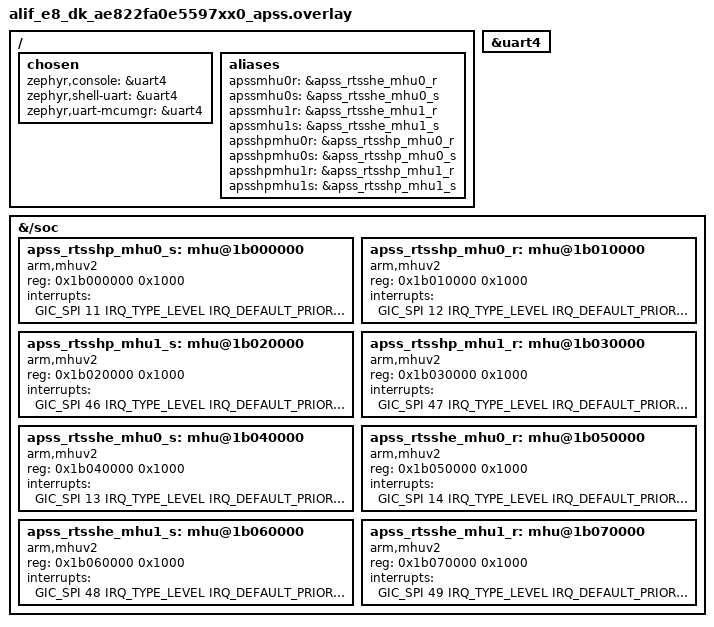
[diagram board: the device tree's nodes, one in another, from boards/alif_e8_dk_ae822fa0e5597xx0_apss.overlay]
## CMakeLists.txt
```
# Copyright (C) Alif Semiconductor - All Rights Reserved.
# Use, distribution and modification of this code is permitted under the
# terms stated in the Alif Semiconductor Software License Agreement
#
# You should have received a copy of the Alif Semiconductor Software
# License Agreement with this file. If not, please write to:
# contact@alifsemi.com, or visit: https://alifsemi.com/license

cmake_minimum_required(VERSION 3.20.0)
find_package(Zephyr REQUIRED HINTS $ENV{ZEPHYR_BASE})
project(ipm_arm_mhu_doorbell)

target_include_directories(app PRIVATE include)

target_sources_ifdef(CONFIG_HE_HP_S  app PRIVATE src/m55he_to_m55hp_initiator.c)
target_sources_ifdef(CONFIG_HP_HE_R  app PRIVATE src/m55hp_to_m55he_responder.c)
target_sources_ifdef(CONFIG_HE_A32_S app PRIVATE src/m55_to_a32_initiator.c)
target_sources_ifdef(CONFIG_A32_HE_R app PRIVATE src/a32_to_m55_responder.c)
```

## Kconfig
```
# Copyright (C) Alif Semiconductor - All Rights Reserved.
# Use, distribution and modification of this code is permitted under the
# terms stated in the Alif Semiconductor Software License Agreement

mainmenu "MHU Doorbell Sample Configuration"

choice
	prompt "MHU doorbell test case"
	default HE_HP_S
	help
	  Select which inter-processor communication test case to build.
	  Exactly one test case is built per image.

config HE_HP_S
	bool "RTSS-HE (M55) to RTSS-HP (M55) initiator/sender"
	help
	  Build the RTSS-HE (M55) to RTSS-HP (M55) shared memory &
	  doorbell initiator/sender.

config HP_HE_R
	bool "RTSS-HP (M55) to RTSS-HE (M55) responder"
	help
	  Build the RTSS-HP (M55) to RTSS-HE (M55) shared memory &
	  doorbell responder.

config HE_A32_S
	bool "RTSS-HE (M55) to APSS (A32) initiator/sender"
	help
	  Build the RTSS-HE (M55) to APSS (A32) shared memory &
	  doorbell initiator/sender.

config A32_HE_R
	bool "APSS (A32) to RTSS-HE (M55) responder"
	help
	  Build the APSS (A32, Zephyr) responder for messages initiated by
	  the RTSS-HE (M55) shared memory & doorbell initiator (counterpart
	  to CONFIG_HE_A32_S).

endchoice

config USE_MHU1
	bool "Use MHU1 instead of MHU0 for inter-core communication"
	default n
	help
	  Select MHU1 channel for communication between M55 cores.
	  Default is MHU0.

source "Kconfig.zephyr"

# Automatically enable power management when one of the pm-system-off-*
# snippets is applied. Those snippets enable the aipm-off DTS node, so the
# default build (without the snippet) is unaffected.
config PM
	default y if $(dt_nodelabel_enabled,aipm_off)

config COUNTER
	default y if $(dt_nodelabel_enabled,aipm_off)
```

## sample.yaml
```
---
sample:
  name: MHU Doorbell & Shared SRAM Sample
tests:
  sample.drivers.ipm.arm_mhu_doorbell:
    tags: doorbell
    platform_allow:
      - alif_e8_dk/ae822fa0e5597xx0/rtss_he
      - alif_e8_dk/ae822fa0e5597xx0/rtss_hp
```

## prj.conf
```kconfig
# The test case (CONFIG_HE_HP_S / CONFIG_HP_HE_R / CONFIG_HE_A32_S /
# CONFIG_A32_HE_R) and options such as CONFIG_USE_MHU1 are selected on the
# command line -- see README.rst. Low-power operation is enabled via the
# pm-system-off-* snippets (PM and COUNTER are turned on automatically in
# Kconfig when the snippet's aipm-off node is present), so no additional
# Kconfig settings are needed here.
```

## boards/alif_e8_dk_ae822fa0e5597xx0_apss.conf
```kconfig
# SPDX-FileCopyrightText: Copyright Alif Semiconductor
# SPDX-License-Identifier: Apache-2.0

# The APSS (A32) board defconfig does not enable MHU support (the A32 normally
# has no MHU nodes). This sample adds them via the board overlay, so pull in
# the SoC MHUv2 support here -- it selects IPM and ARM_MHUV2 -- for the A32
# responder build (CONFIG_A32_HE_R).
CONFIG_SOC_SUPPORT_ARM_MHUV2=y
```

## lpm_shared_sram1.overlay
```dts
/* Copyright (C) Alif Semiconductor - All Rights Reserved.
 * Use, distribution and modification of this code is permitted under the
 * terms stated in the Alif Semiconductor Software License Agreement
 *
 * You should have received a copy of the Alif Semiconductor Software
 * License Agreement with this file. If not, please write to:
 * contact@alifsemi.com, or visit: https://alifsemi.com/license
 *
 * Keep the cross-core shared heap (SRAM1) powered AND keep the VBAT_AON power
 * domain (which hosts the LPRTC idle-timer) alive when the pm-system-off-*
 * snippets are applied.
 *
 * The HE<->HP doorbell protocol exchanges data through a struct sys_heap that
 * lives in SRAM1 (0x027DC000 / 0x027DC800), and HE uses the LPRTC
 * (rtc0 = lprtc@42000000, chosen zephyr,cortex-m-idle-timer) to wake itself
 * from PM_STATE_SUSPEND_TO_IDLE for each timed k_sleep().
 *
 * The Secure Enclave only lowers a power domain / drops a memory block when
 * ALL participating cores vote for it. The pm-system-off-* snippets set the
 * run profile to:
 *   - retain ONLY MRAM (memory-blocks = <ALIF_MRAM_MASK>)
 *   - keep ONLY SSE700_AON + SYST powered (power-domains = 0x44), dropping
 *     VBAT_AON.
 * The LPRTC at 0x42000000 lives in the VBAT_AON domain. When only one core is
 * PM-managed the other (fully-on) core keeps both SRAM1 and VBAT_AON alive, so
 * the protocol works. As soon as BOTH cores run a snippet, neither votes to
 * keep VBAT_AON powered -> the SE gates it -> the LPRTC stops counting -> HE's
 * very first k_sleep() never wakes and the system HANGS. (The same applies to
 * SRAM1 retention for the shared heap.)
 *
 * Override the run profile to (a) retain SRAM1 and (b) keep VBAT_AON powered.
 * This must be applied AFTER the snippet overlay. Only a command-line
 * EXTRA_DTC_OVERLAY_FILE is applied after the snippet (the app's
 * boards/<board>.overlay and any overlay appended from CMakeLists before
 * find_package are applied BEFORE the snippet and lose to it). So pass this
 * file explicitly on the west command line, e.g.:
 *   HE: -DEXTRA_DTC_OVERLAY_FILE="lpuart.overlay;lpm_shared_sram1.overlay"
 *   HP: -DEXTRA_DTC_OVERLAY_FILE=lpm_shared_sram1.overlay
 */

&aipm_run_default {
	/* Retain the shared heap (SRAM1) in addition to MRAM. */
	memory-blocks = <(ALIF_MRAM_MASK | ALIF_SRAM1_MASK)>;
	/* Keep VBAT_AON powered so the LPRTC idle-timer keeps ticking and can
	 * wake HE from SUSPEND_TO_IDLE; SSE700_AON + SYST as per the snippet.
	 */
	aipm-power-domains = <(ALIF_PD_VBAT_AON_MASK |
			       ALIF_PD_SSE700_AON_MASK |
			       ALIF_PD_SYST_MASK)>;
};

/* HE idles into PM_STATE_SUSPEND_TO_IDLE during the protocol; the
 * pm-system-off-he snippet already enables this node. The pm-system-off-hp
 * snippet does not, so enable it here. Suspend-to-idle uses the IWIC, which
 * wakes on the MHU RX IRQ (and, on HE, the rtc0 idle-timer), so no extra wake
 * configuration is needed. (HP itself uses SOFT_OFF, but leaving this enabled
 * is harmless as HP locks SUSPEND_TO_IDLE out at runtime.)
 */
&suspend_idle {
	status = "okay";
};

/* Keep SRAM1 powered across SOFT_OFF so the cross-core shared heap memory stays
 * valid while a core is off. The sample re-initialises the heap on each
 * reset-based wake, so this only keeps SRAM1 powered and does not rely on any
 * state surviving a SOFT_OFF cycle. The pm-system-off-*
 * snippets retain only MRAM (+SERAM on HP) in the off profile, which would drop
 * SRAM1 when a core powers off. Setting only memory-blocks here leaves the
 * snippet's wakeup-events / ewic-cfg untouched. (HP's MHU wake comes from the
 * M55 EWIC auto-monitoring enabled NVIC IRQs 0-63 -- MHU0=41, MHU1=43 -- not
 * from the off-profile AON ewic-cfg.)
 */
&off_profile_soft_off {
	memory-blocks = <(ALIF_MRAM_MASK | ALIF_SERAM_MASK | ALIF_SRAM1_MASK)>;
};
```

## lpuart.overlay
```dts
/* Copyright (C) Alif Semiconductor - All Rights Reserved.
 * Use, distribution and modification of this code is permitted under the
 * terms stated in the Alif Semiconductor Software License Agreement
 *
 * You should have received a copy of the Alif Semiconductor Software
 * License Agreement with this file. If not, please write to:
 * contact@alifsemi.com, or visit: https://alifsemi.com/license
 */

&uart2 {
	status = "disabled";
};

&lpuart {
	current-speed = <115200>;
	dlf = <13>;
	/*/delete-property/ dlf;*/
	status = "okay";
	/delete-property/ pinctrl-1; // = <&pinctrl_lpuart_sleep>;
	pinctrl-names = "default";
};

&pinctrl {
	pinctrl_lpuart: pinctrl_lpuart {
		group0 {
			pinmux = < PIN_P9_1__LPUART_RX_B >,
				 < PIN_P9_2__LPUART_TX_B >;
		};
	};
};
/ {
	chosen {
		zephyr,console = &lpuart;
		zephyr,shell-uart = &lpuart;
		zephyr,uart-mcumgr = &lpuart;
	};
};
/*
 * Enable PM_STATE_SOFT_OFF wake for the HE core via the always-on LPTIMER0.
 *
 * The pm-system-off-he snippet only configures the S2RAM off-profiles
 * (off_profile_standby / off_profile_stop -> LPRTC wake) and leaves
 * off_profile_soft_off at its default (wakeup-events = 0, ewic-cfg = 0), so
 * SOFT_OFF on HE has no wake source and never resumes. Mirror the HP snippet
 * and wake SOFT_OFF from LPTIMER0 (VBAT timer, EWIC VBAT_TIMER).
 *
 * Only a command-line EXTRA_DTC_OVERLAY_FILE is applied AFTER the snippet, so
 * this override must live in an overlay passed on the west command line (this
 * file). Enabling timer0 also lets main.c arm LPTIMER0 before entering
 * SOFT_OFF, since the LPRTC idle-timer is powered down in that profile.
 */
&timer0 {
	status = "okay";
};

/*
 * The pm-system-off-he snippet sets aipm_off vtor-address = 0x0, i.e. it tells
 * the Secure Enclave to restore VTOR to TCM (0x0) when the core wakes from the
 * off profile. That is correct for a TCM-boot image (S2RAM resume in place),
 * but this build boots from MRAM (VTOR = 0x80000000). On wake from SOFT_OFF the
 * SE would jump to the empty TCM at 0x0 and the core would never restart, so no
 * reset is observed. Point the wake vector back at the MRAM image start so
 * SOFT_OFF wakeup performs a clean reset/reboot (as it does on the HP core,
 * whose snippet does not override vtor-address).
 */
&aipm_off {
	vtor-address = <0x80000000>;
};

&off_profile_soft_off {
	status = "okay";
	/* Keep SRAM1 powered across SOFT_OFF so the cross-core shared heap
	 * memory stays valid while HE is off. The sample re-initialises the
	 * heap on each reset-based wake and does not rely on any state
	 * surviving a SOFT_OFF cycle.
	 */
	memory-blocks = <(ALIF_MRAM_MASK | ALIF_SERAM_MASK | ALIF_SRAM1_MASK)>;
	wakeup-events = <ALIF_WE_LPTIMER0>;
	ewic-cfg = <ALIF_EWIC_VBAT_TIMER>;
};

/*
 * The m55he_to_m55hp_initiator.c flow re-enters SOFT_OFF between doorbell
 * exchanges and arms LPTIMER0 for a 2 s wake. Lower the SOFT_OFF (subsys_off)
 * min-residency below 2 s (snippet default is 25 s) so the PM policy actually
 * selects SOFT_OFF for that 2 s k_sleep().
 */
&subsys_off {
	min-residency-us = <500000>;
};
```

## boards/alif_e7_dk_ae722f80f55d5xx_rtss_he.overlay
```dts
/* Copyright (C) Alif Semiconductor - All Rights Reserved.
 * Use, distribution and modification of this code is permitted under the
 * terms stated in the Alif Semiconductor Software License Agreement
 *
 * You should have received a copy of the Alif Semiconductor Software
 * License Agreement with this file. If not, please write to:
 * contact@alifsemi.com, or visit: https://alifsemi.com/license
 *
 */
#include "alif_ensemble_dk.overlay"
```

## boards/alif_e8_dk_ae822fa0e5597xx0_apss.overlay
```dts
/*
 * SPDX-FileCopyrightText: Copyright Alif Semiconductor
 * SPDX-License-Identifier: Apache-2.0
 *
 * APSS (A32) board overlay for the MHU doorbell sample.
 *
 * The A32 is the peer of the RTSS-HE core: it receives the doorbell the
 * RTSS-HE initiator sends and replies back. Unlike the M55 cores (NVIC), the
 * A32 reaches the MHU register frames through the GIC.
 *
 * Register bases and GIC SPI interrupts are the A32-side MHU frames for the
 * RTSS-HE and RTSS-HP channels on the Alif devkit-e8:
 *   hp_mhu0_tx @ 0x1b000000  GIC_SPI 11
 *   hp_mhu0_rx @ 0x1b010000  GIC_SPI 12
 *   hp_mhu1_tx @ 0x1b020000  GIC_SPI 46
 *   hp_mhu1_rx @ 0x1b030000  GIC_SPI 47
 *   he_mhu0_tx @ 0x1b040000  GIC_SPI 13
 *   he_mhu0_rx @ 0x1b050000  GIC_SPI 14
 *   he_mhu1_tx @ 0x1b060000  GIC_SPI 48
 *   he_mhu1_rx @ 0x1b070000  GIC_SPI 49
 *
 * The shared SRAM1 heap (0x027DDxxx) is not in the A32's default MMU map; the
 * responder maps it at runtime, non-cacheable, via k_mem_map_phys_bare().
 */

#include <zephyr/dt-bindings/interrupt-controller/arm-gic.h>

/ {
	chosen {
		zephyr,console = &uart4;
		zephyr,shell-uart = &uart4;
		zephyr,uart-mcumgr = &uart4;
	};

	aliases {
		apssmhu0r = &apss_rtsshe_mhu0_r;
		apssmhu0s = &apss_rtsshe_mhu0_s;
		apssmhu1r = &apss_rtsshe_mhu1_r;
		apssmhu1s = &apss_rtsshe_mhu1_s;
		apsshpmhu0r = &apss_rtsshp_mhu0_r;
		apsshpmhu0s = &apss_rtsshp_mhu0_s;
		apsshpmhu1r = &apss_rtsshp_mhu1_r;
		apsshpmhu1s = &apss_rtsshp_mhu1_s;
	};
};

&uart4 {
	status = "okay";
};

&{/soc} {
	/* MHU0 sender: A32 sends to RTSS-HP */
	apss_rtsshp_mhu0_s: mhu@1b000000 {
		compatible = "arm,mhuv2";
		reg = <0x1b000000 0x1000>;
		interrupts = <GIC_SPI 11 IRQ_TYPE_LEVEL IRQ_DEFAULT_PRIORITY>;
		interrupt-names = "tx";
		status = "okay";
	};

	/* MHU0 receiver: A32 receives from RTSS-HP */
	apss_rtsshp_mhu0_r: mhu@1b010000 {
		compatible = "arm,mhuv2";
		reg = <0x1b010000 0x1000>;
		interrupts = <GIC_SPI 12 IRQ_TYPE_LEVEL IRQ_DEFAULT_PRIORITY>;
		interrupt-names = "rx";
		status = "okay";
	};

	/* MHU1 sender: A32 sends to RTSS-HP */
	apss_rtsshp_mhu1_s: mhu@1b020000 {
		compatible = "arm,mhuv2";
		reg = <0x1b020000 0x1000>;
		interrupts = <GIC_SPI 46 IRQ_TYPE_LEVEL IRQ_DEFAULT_PRIORITY>;
		interrupt-names = "tx";
		status = "okay";
	};

	/* MHU1 receiver: A32 receives from RTSS-HP */
	apss_rtsshp_mhu1_r: mhu@1b030000 {
		compatible = "arm,mhuv2";
		reg = <0x1b030000 0x1000>;
		interrupts = <GIC_SPI 47 IRQ_TYPE_LEVEL IRQ_DEFAULT_PRIORITY>;
		interrupt-names = "rx";
		status = "okay";
	};

	/* MHU0 sender: A32 sends to RTSS-HE */
	apss_rtsshe_mhu0_s: mhu@1b040000 {
		compatible = "arm,mhuv2";
		reg = <0x1b040000 0x1000>;
		interrupts = <GIC_SPI 13 IRQ_TYPE_LEVEL IRQ_DEFAULT_PRIORITY>;
		interrupt-names = "tx";
		status = "okay";
	};

	/* MHU0 receiver: A32 receives from RTSS-HE */
	apss_rtsshe_mhu0_r: mhu@1b050000 {
		compatible = "arm,mhuv2";
		reg = <0x1b050000 0x1000>;
		interrupts = <GIC_SPI 14 IRQ_TYPE_LEVEL IRQ_DEFAULT_PRIORITY>;
		interrupt-names = "rx";
		status = "okay";
	};

	/* MHU1 sender: A32 sends to RTSS-HE */
	apss_rtsshe_mhu1_s: mhu@1b060000 {
		compatible = "arm,mhuv2";
		reg = <0x1b060000 0x1000>;
		interrupts = <GIC_SPI 48 IRQ_TYPE_LEVEL IRQ_DEFAULT_PRIORITY>;
		interrupt-names = "tx";
		status = "okay";
	};

	/* MHU1 receiver: A32 receives from RTSS-HE */
	apss_rtsshe_mhu1_r: mhu@1b070000 {
		compatible = "arm,mhuv2";
		reg = <0x1b070000 0x1000>;
		interrupts = <GIC_SPI 49 IRQ_TYPE_LEVEL IRQ_DEFAULT_PRIORITY>;
		interrupt-names = "rx";
		status = "okay";
	};
};
```

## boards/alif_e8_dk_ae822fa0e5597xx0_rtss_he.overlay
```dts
/* Copyright (C) Alif Semiconductor - All Rights Reserved.
 * Use, distribution and modification of this code is permitted under the
 * terms stated in the Alif Semiconductor Software License Agreement
 *
 * You should have received a copy of the Alif Semiconductor Software
 * License Agreement with this file. If not, please write to:
 * contact@alifsemi.com, or visit: https://alifsemi.com/license
 *
 */
#include "alif_ensemble_dk.overlay"
/*
 * /{
 *	chosen {
 *		zephyr,console = &uart4;
 *		zephyr,shell-uart = &uart4;
 *		zephyr,uart-mcumgr = &uart4;
 *	};
 * };
 *
 * &uart4 {
 *	status = "okay";
 * };
 */
```

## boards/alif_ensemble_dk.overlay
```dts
/* Copyright (C) Alif Semiconductor - All Rights Reserved.
 * Use, distribution and modification of this code is permitted under the
 * terms stated in the Alif Semiconductor Software License Agreement
 *
 * You should have received a copy of the Alif Semiconductor Software
 * License Agreement with this file. If not, please write to:
 * contact@alifsemi.com, or visit: https://alifsemi.com/license
 *
 */

/{
	aliases {
		apssmhu0r = &apss_rtsshe_mhu0_r;
		apssmhu0s = &rtsshe_apss_mhu0_s;
		apssmhu1r = &apss_rtsshe_mhu1_r;
		apssmhu1s = &rtsshe_apss_mhu1_s;
		rtssmhu0r = &rtsshp_rtsshe_mhu0_r;
		rtssmhu0s = &rtsshe_rtsshp_mhu0_s;
		rtssmhu1r = &rtsshp_rtsshe_mhu1_r;
		rtssmhu1s = &rtsshe_rtsshp_mhu1_s;
	};
};
```

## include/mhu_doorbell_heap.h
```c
/* Copyright (C) Alif Semiconductor - All Rights Reserved.
 * Use, distribution and modification of this code is permitted under the
 * terms stated in the Alif Semiconductor Software License Agreement
 *
 * You should have received a copy of the Alif Semiconductor Software
 * License Agreement with this file. If not, please write to:
 * contact@alifsemi.com, or visit: https://alifsemi.com/license
 *
 * Shared SRAM1 cross-core heap layout for the MHU doorbell sample.
 *
 * Each shared heap is a struct sys_heap control block immediately followed by
 * the memory it manages, both placed in shared SRAM1 so the two participating
 * cores operate on the same heap instance. The control block plus managed
 * memory occupy one SHARED_HEAP_SPAN region; the managed area itself is
 * SHARED_HEAP_SIZE bytes. There is one heap per MHU channel.
 *
 * The addresses are a fixed contract shared by every participant (M55-HE,
 * M55-HP and the A32/APSS side), so they live in one header rather than being
 * duplicated per test case. The A32 (HE<->A32) heaps are page-aligned and each
 * whole span fits in one 4 KB page so the A32 side can reach every block
 * through a single mapping.
 *
 * The region sits 0x24000 below the end of SRAM1, whose location differs per
 * SoC series:
 *   E8: SRAM1 0x02400000 (4 MB)   -> SHARED_HEAP_BASE 0x027DC000
 *   E7: SRAM1 0x08000000 (2.5 MB) -> SHARED_HEAP_BASE 0x0825C000
 * The base is selected by SoC series rather than taken from the devicetree
 * because the APSS devicetree has no sram1 node.
 *
 *   SRAM1 layout relative to SHARED_HEAP_BASE (ctrl / mem, each span 0x800):
 *     HE<->HP   MHU0: ctrl +0x0000, mem +0x0100
 *     HE<->HP   MHU1: ctrl +0x0800, mem +0x0900
 *     HE<->A32  MHU0: ctrl +0x1000, mem +0x1100
 *     HE<->A32  MHU1: ctrl +0x2000, mem +0x2100
 */

#ifndef MHU_DOORBELL_HEAP_H
#define MHU_DOORBELL_HEAP_H

#if defined(CONFIG_SOC_SERIES_E8)
#define SHARED_HEAP_BASE  0x027DC000
#elif defined(CONFIG_SOC_SERIES_E7)
#define SHARED_HEAP_BASE  0x0825C000
#else
#error "Shared SRAM1 heap location is not defined for this SoC"
#endif

#define SHARED_HEAP_SIZE  0x700   /* managed memory size */
#define SHARED_HEAP_SPAN  0x800   /* ctrl block + managed memory */

/* M55-HE <-> M55-HP heaps (one per MHU channel). */
#define SHARED_HEAP_HEHP_MHU0_CTRL  (SHARED_HEAP_BASE + 0x0000)
#define SHARED_HEAP_HEHP_MHU0_MEM   (SHARED_HEAP_BASE + 0x0100)
#define SHARED_HEAP_HEHP_MHU1_CTRL  (SHARED_HEAP_BASE + 0x0800)
#define SHARED_HEAP_HEHP_MHU1_MEM   (SHARED_HEAP_BASE + 0x0900)

/* M55-HE <-> A32 (APSS) heaps (one per MHU channel). */
#define SHARED_HEAP_HEA32_MHU0_CTRL (SHARED_HEAP_BASE + 0x1000)
#define SHARED_HEAP_HEA32_MHU0_MEM  (SHARED_HEAP_BASE + 0x1100)
#define SHARED_HEAP_HEA32_MHU1_CTRL (SHARED_HEAP_BASE + 0x2000)
#define SHARED_HEAP_HEA32_MHU1_MEM  (SHARED_HEAP_BASE + 0x2100)

#endif /* MHU_DOORBELL_HEAP_H */
```

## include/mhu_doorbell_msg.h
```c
/* Copyright (C) Alif Semiconductor - All Rights Reserved.
 * Use, distribution and modification of this code is permitted under the
 * terms stated in the Alif Semiconductor Software License Agreement
 *
 * You should have received a copy of the Alif Semiconductor Software
 * License Agreement with this file. If not, please write to:
 * contact@alifsemi.com, or visit: https://alifsemi.com/license
 *
 * Cross-core wire contract for the MHU doorbell sample.
 *
 * The doorbell carries a 32-bit value (a shared-SRAM address); the data it
 * points at is a struct shared_msg. Every participant -- M55-HE, M55-HP and
 * the A32/APSS side -- MUST agree on this layout and on the magic values,
 * so it lives in one shared header rather than being duplicated per test
 * case.
 *
 * Shared memory layout (struct shared_msg):
 *   [0x00] magic      - identifies the writer (see MAGIC_* below)
 *   [0x04] msg_id     - incrementing message counter
 *   [0x08] data_len   - number of payload bytes (max MAX_PAYLOAD)
 *   [0x0C] data[240]  - payload
 *   [0xFC] checksum   - sum of payload bytes
 */

#ifndef MHU_DOORBELL_MSG_H
#define MHU_DOORBELL_MSG_H

#include <stdint.h>

#define MAX_PAYLOAD 240

/* Magic values identifying which core wrote the block. */
#define MAGIC_HE  0xCAFE0E00   /* Written by M55-HE  */
#define MAGIC_HP  0xCAFE0F00   /* Written by M55-HP  */
#define MAGIC_A32 0xA32F055E   /* Written by A32     */
#define MAGIC_M55 0xF055EA32   /* Written by M55 (A32 protocol) */

struct shared_msg {
	uint32_t magic;
	uint32_t msg_id;
	uint32_t data_len;
	uint8_t  data[MAX_PAYLOAD];
	uint32_t checksum;
};

#endif /* MHU_DOORBELL_MSG_H */
```

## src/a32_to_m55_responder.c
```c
/*
 * SPDX-FileCopyrightText: Copyright Alif Semiconductor
 * SPDX-License-Identifier: Apache-2.0
 *
 * MHU Doorbell + Shared SRAM1 heap test: A32 (responder) <-> M55-HE/HP (initiator)
 *
 * Zephyr-on-A32 counterpart to src/m55_to_a32_initiator.c, using the Zephyr
 * IPM/MHU driver. The A32 has a separate MHU to each M55 core, so the responder
 * listens on both the HE and HP channels and replies on whichever rang; the
 * initiator can therefore run on either M55 core.
 *
 * Protocol:
 *   - A struct sys_heap and the memory it manages both live in shared SRAM1.
 *     The M55 initiator owns the heap (it does the alloc and the free); A32
 *     only reads/writes the data block whose physical address the M55 passes
 *     over the MHU doorbell.
 *   - The M55 initiator allocates a block, writes a payload (magic MAGIC_HE),
 *     and rings the doorbell with the block address.
 *   - A32 (responder) reads/validates the block, writes its response into the
 *     same block (magic MAGIC_A32, payload echoed back), and rings the
 *     doorbell back with the block address as an acknowledgment.
 *
 * IMPORTANT: D-cache coherency
 *   The A32 runs under an MMU, so the shared SRAM1 heap page is mapped
 *   non-cacheable (K_MEM_CACHE_NONE), so A32 accesses go straight to memory and
 *   need no cache maintenance; the M55 initiator (D-cache enabled) cleans after
 *   writing and invalidates before reading. The doorbell carries a physical
 *   address, which A32 translates into its non-cacheable mapping.
 *
 * Shared memory layout (struct shared_msg):
 *   [0x00] magic      - 0xCAFE0E00 from the M55 initiator, 0xA32F055E by A32
 *   [0x04] msg_id     - incrementing message counter
 *   [0x08] data_len   - number of payload bytes (max 240)
 *   [0x0C] data[240]  - payload
 *   [0xFC] checksum   - sum of payload bytes
 *
 * Test flow (per iteration):
 *   1. A32 waits for a doorbell from either M55 core (MHU RX interrupt)
 *   2. A32 reads and validates the block via the non-cacheable mapping
 *   3. A32 writes its response into the same block
 *   4. A32 rings the doorbell back to that core with the block address
 */

#include <zephyr/kernel.h>
#include <zephyr/sys/printk.h>
#include <zephyr/drivers/ipm.h>
#include <zephyr/kernel/mm.h>
#include <string.h>

#include "mhu_doorbell_msg.h"
#include "mhu_doorbell_heap.h"

#define ITERATIONS       25
#define MAX_ERRORS       10
#define RX_TIMEOUT_MS    5000  /* Timeout waiting for a doorbell     */
#define TX_TIMEOUT_MS    1000  /* Timeout waiting for TX completion  */

/* Shared SRAM1 cross-core heap for M55 <-> A32 communication. A32 does not
 * operate the Zephyr heap; it only reads/writes the block the M55 passes over
 * the doorbell, and range-checks that address against this heap's span.
 * Addresses come from mhu_doorbell_heap.h and must match the M55 initiator.
 * The HE and HP initiators use the same HEA32 heap region (one peer at a time).
 */
#if IS_ENABLED(CONFIG_USE_MHU1)
#define SHARED_HEAP_CTRL  SHARED_HEAP_HEA32_MHU1_CTRL
#else
#define SHARED_HEAP_CTRL  SHARED_HEAP_HEA32_MHU0_CTRL
#endif

/* MHU aliases as seen from the A32 (APSS) side. The A32 has a separate MHU to
 * each M55 core, so the responder listens on both the HE and the HP channel
 * (for the selected MHU instance) and replies on whichever one rang -- the
 * initiator can therefore run on either M55 core with no rebuild here. The A32
 * board overlay provides both alias sets.
 */
#if IS_ENABLED(CONFIG_USE_MHU1)
#define MHU_NAME    "MHU1"
#define HE_R_ALIAS  apssmhu1r
#define HE_S_ALIAS  apssmhu1s
#define HP_R_ALIAS  apsshpmhu1r
#define HP_S_ALIAS  apsshpmhu1s
#else
#define MHU_NAME    "MHU0"
#define HE_R_ALIAS  apssmhu0r
#define HE_S_ALIAS  apssmhu0s
#define HP_R_ALIAS  apsshpmhu0r
#define HP_S_ALIAS  apsshpmhu0s
#endif

const struct device *mhu_he_rx_dev;  /* receive from M55-HE */
const struct device *mhu_he_tx_dev;  /* send to M55-HE      */
const struct device *mhu_hp_rx_dev;  /* receive from M55-HP */
const struct device *mhu_hp_tx_dev;  /* send to M55-HP      */

static volatile bool doorbell_tx_done;
static volatile uint32_t rx_doorbell_addr;
static const struct device *volatile active_tx_dev;
static const char *volatile active_peer;

/* Signalled from the MHU RX interrupt so the main loop can block until a
 * doorbell actually arrives instead of polling.
 */
static K_SEM_DEFINE(doorbell_rx_sem, 0, 1);

static void mhu_rx_callback(const struct device *dev, void *user_data,
			    uint32_t id, volatile void *data)
{
	ARG_UNUSED(user_data);
	ARG_UNUSED(id);

	/* Keep the ISR minimal: no printk here (blocking/latency in interrupt
	 * context). Record which peer rang so the reply goes back on the same
	 * channel; the main loop logs in thread context.
	 */
	rx_doorbell_addr = *((uint32_t *)data);
	if (dev == mhu_he_rx_dev) {
		active_tx_dev = mhu_he_tx_dev;
		active_peer = "M55-HE";
	} else {
		active_tx_dev = mhu_hp_tx_dev;
		active_peer = "M55-HP";
	}
	k_sem_give(&doorbell_rx_sem);
}

static void mhu_tx_callback(const struct device *dev, void *user_data,
			    uint32_t id, volatile void *data)
{
	ARG_UNUSED(dev);
	ARG_UNUSED(user_data);
	ARG_UNUSED(id);
	ARG_UNUSED(data);

	/* Keep the ISR minimal: no printk here. */
	doorbell_tx_done = true;
}

static uint32_t calc_checksum(const uint8_t *buf, uint32_t len)
{
	uint32_t sum = 0;

	for (uint32_t i = 0; i < len; i++) {
		sum += buf[i];
	}
	return sum;
}

int main(void)
{
	int iter;
	uint8_t *heap_virt;

	printk("\n==========================================\n");
	printk("A32 <-> M55-HE/HP : %s Doorbell + Shared SRAM1 heap (responder)\n",
	       MHU_NAME);
	printk("  Shared heap ctrl: 0x%08x (span 0x%x)\n",
	       SHARED_HEAP_CTRL, SHARED_HEAP_SPAN);
	printk("==========================================\n");

	/* Map the shared SRAM1 heap page non-cacheable so A32 sees the data the
	 * M55 initiator flushes (and vice versa) without any cache maintenance.
	 * The doorbell carries a physical block address; translate it into this
	 * mapping via (heap_virt + (phys - SHARED_HEAP_CTRL)).
	 */
	k_mem_map_phys_bare(&heap_virt, SHARED_HEAP_CTRL, SHARED_HEAP_SPAN,
			    K_MEM_CACHE_NONE | K_MEM_PERM_RW);

	mhu_he_rx_dev = DEVICE_DT_GET(DT_ALIAS(HE_R_ALIAS));
	mhu_he_tx_dev = DEVICE_DT_GET(DT_ALIAS(HE_S_ALIAS));
	mhu_hp_rx_dev = DEVICE_DT_GET(DT_ALIAS(HP_R_ALIAS));
	mhu_hp_tx_dev = DEVICE_DT_GET(DT_ALIAS(HP_S_ALIAS));

	if (!device_is_ready(mhu_he_rx_dev) || !device_is_ready(mhu_he_tx_dev) ||
	    !device_is_ready(mhu_hp_rx_dev) || !device_is_ready(mhu_hp_tx_dev)) {
		printk("ERROR: %s devices not ready!\n", MHU_NAME);
		return -1;
	}
	printk("%s devices ready\n", MHU_NAME);

	ipm_register_callback(mhu_he_rx_dev, mhu_rx_callback, NULL);
	ipm_register_callback(mhu_he_tx_dev, mhu_tx_callback, NULL);
	ipm_register_callback(mhu_hp_rx_dev, mhu_rx_callback, NULL);
	ipm_register_callback(mhu_hp_tx_dev, mhu_tx_callback, NULL);
	ipm_set_enabled(mhu_he_rx_dev, true);
	ipm_set_enabled(mhu_hp_rx_dev, true);

	printk("Waiting for M55-HE/HP doorbells...\n\n");

	int completed = 0;
	int errors = 0;

	for (iter = 0; iter < ITERATIONS; iter++) {
		/* --- Wait for a doorbell from either M55 core --- */
		if (iter == 0) {
			/* First iteration: wait indefinitely for the M55 to boot */
			k_sem_take(&doorbell_rx_sem, K_FOREVER);
		} else if (k_sem_take(&doorbell_rx_sem,
				      K_MSEC(RX_TIMEOUT_MS)) != 0) {
			printk("ERROR: Timeout waiting for doorbell "
			       "(%d ms)\n", RX_TIMEOUT_MS);
			break;
		}

		unsigned int key = irq_lock();
		uint32_t rx_addr = rx_doorbell_addr;
		const struct device *tx_dev = active_tx_dev;
		const char *peer = active_peer;

		irq_unlock(key);

		printk("A32: Doorbell RX from %s addr=0x%08x\n", peer, rx_addr);

		/* --- Range-check the untrusted doorbell address --- */
		if (rx_addr < SHARED_HEAP_CTRL ||
		    rx_addr + sizeof(struct shared_msg) >
			    SHARED_HEAP_CTRL + SHARED_HEAP_SPAN) {
			printk("[%d] ERROR: doorbell addr 0x%08x outside heap "
			       "[0x%08x, 0x%08x)\n", iter, rx_addr,
			       SHARED_HEAP_CTRL,
			       SHARED_HEAP_CTRL + SHARED_HEAP_SPAN);
			errors++;
			if (errors >= MAX_ERRORS)
				break;
			continue;
		}

		/* Translate the physical block address into the non-cacheable
		 * mapping (no cache maintenance needed on the A32 side).
		 */
		volatile struct shared_msg *msg = (volatile struct shared_msg *)
				(heap_virt + (rx_addr - SHARED_HEAP_CTRL));

		if (msg->magic != MAGIC_HE) {
			printk("[%d] ERROR: Bad magic 0x%08x (expected 0x%08x)\n",
			       iter, msg->magic, MAGIC_HE);
			errors++;
			if (errors >= MAX_ERRORS)
				break;
			continue;
		}

		uint32_t rx_len = msg->data_len;

		if (rx_len > MAX_PAYLOAD) {
			printk("[%d] ERROR: data_len %u exceeds MAX_PAYLOAD\n",
			       iter, rx_len);
			errors++;
			if (errors >= MAX_ERRORS)
				break;
			continue;
		}

		uint32_t computed = calc_checksum((const uint8_t *)msg->data,
						  rx_len);
		printk("[%d] %s->A32: block @ 0x%08x msg_id=%u len=%u "
		       "cksum=0x%x/0x%x %s\n", iter, peer, rx_addr, msg->msg_id,
		       rx_len, computed, msg->checksum,
		       (computed == msg->checksum) ? "PASS" : "FAIL");

		if (computed != msg->checksum) {
			errors++;
			if (errors >= MAX_ERRORS)
				break;
			continue;
		}

		/* --- Write the response into the same block (echo payload) --- */
		msg->magic = MAGIC_A32;
		/* msg_id, data[] and data_len are the M55 payload echoed back. */
		msg->checksum = calc_checksum((const uint8_t *)msg->data, rx_len);

		/* --- Ring doorbell back to the initiator with the block address --- */
		doorbell_tx_done = false;
		uint32_t doorbell_val = rx_addr;

		int send_ret = ipm_send(tx_dev, 0, 0, &doorbell_val, 4);

		if (send_ret != 0) {
			printk("ERROR: ipm_send failed: %d\n", send_ret);
			errors++;
			if (errors >= MAX_ERRORS)
				break;
			continue;
		}

		int tx_waited = 0;

		while (!doorbell_tx_done && tx_waited < TX_TIMEOUT_MS) {
			k_sleep(K_MSEC(1));
			tx_waited++;
		}
		if (!doorbell_tx_done) {
			printk("ERROR: Timeout waiting for TX completion "
			       "(%d ms)\n", TX_TIMEOUT_MS);
			break;
		}

		printk("[%d] A32->%s: block @ 0x%08x msg_id=%u len=%u "
		       "cksum=0x%x Complete\n\n", iter, peer, rx_addr, msg->msg_id,
		       rx_len, msg->checksum);
		completed++;
	}

	ipm_set_enabled(mhu_he_rx_dev, false);
	ipm_set_enabled(mhu_hp_rx_dev, false);
	printk("Done: %d/%d passed, %d failed\n",
	       completed, ITERATIONS, errors);
	return (completed + errors == ITERATIONS) ? 0 : -1;
}
```

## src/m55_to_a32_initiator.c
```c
/* Copyright (C) Alif Semiconductor - All Rights Reserved.
 * Use, distribution and modification of this code is permitted under the
 * terms stated in the Alif Semiconductor Software License Agreement
 *
 * You should have received a copy of the Alif Semiconductor Software
 * License Agreement with this file. If not, please write to:
 * contact@alifsemi.com, or visit: https://alifsemi.com/license
 *
 * MHU Doorbell + Shared SRAM1 heap test: M55 (initiator) <-> A32 (responder)
 *
 * Runs on either M55 core (RTSS-HE or RTSS-HP); the board overlay selects the
 * MHU instance the apssmhu* aliases resolve to.
 *
 * Protocol:
 *   - A struct sys_heap and the memory it manages both live in shared
 *     SRAM1. M55 operates on the heap; A32 only reads/writes the data block
 *     whose physical address M55 passes over the MHU doorbell (A32 cannot
 *     operate on the Zephyr heap, so M55 owns both the alloc and the free).
 *   - M55 (initiator) dynamically allocates a message block from the shared
 *     heap, fills it with a payload, and rings the MHU doorbell passing the
 *     physical address of the allocated block.
 *   - A32 (responder) maps the shared SRAM non-cacheable, reads/validates the
 *     block, writes its response into the same block, and rings the doorbell
 *     back with the block address as an acknowledgment.
 *   - M55 invalidates its D-cache, validates A32's response, and frees the
 *     block back to the shared heap.
 *
 * IMPORTANT: D-cache coherency
 *   A32 accesses SRAM via a non-cacheable mapping, but the M55 has
 *   D-cache enabled. After writing the shared block the M55 cleans (flushes)
 *   its D-cache; before reading A32's response it invalidates its D-cache.
 *
 * Shared memory layout (struct shared_msg):
 *   [0x00] magic      - 0xCAFE0E00 when written by M55, 0xA32F055E by A32
 *   [0x04] msg_id     - incrementing message counter
 *   [0x08] data_len   - number of payload bytes (max 240)
 *   [0x0C] data[240]  - payload
 *   [0xFC] checksum   - sum of payload bytes
 *
 * Test flow (per iteration):
 *   1. M55 allocates a block from the shared heap, writes test data, flushes
 *   2. M55 rings doorbell to A32 with the allocated block address
 *   3. M55 waits for A32's acknowledgment doorbell
 *   4. M55 invalidates D-cache, validates A32's response, frees the block
 */

#include <zephyr/kernel.h>
#include <zephyr/sys/printk.h>
#include <zephyr/sys/sys_heap.h>
#include <zephyr/drivers/ipm.h>
#include <zephyr/cache.h>
#include <string.h>

#include "mhu_doorbell_msg.h"
#include "mhu_doorbell_heap.h"

#define CACHE_INVALIDATE(addr, size) sys_cache_data_invd_range((void *)(addr), (size))
#define CACHE_CLEAN(addr, size)      sys_cache_data_flush_range((void *)(addr), (size))

#define ITERATIONS       25
#define MAX_ERRORS       10
#define RX_TIMEOUT_MS    5000
#define TX_TIMEOUT_MS    1000

/* Shared SRAM1 cross-core heap for M55 <-> A32 communication.
 * The struct sys_heap control block and the managed memory both live in
 * shared SRAM1 so M55 can allocate a block whose physical address is passed
 * to A32 over the doorbell. A32 only reads/writes the data block (it cannot
 * operate on the Zephyr heap), so M55 owns both the alloc and the free.
 *
 * The heap base is page-aligned and the whole span (0x800) fits in one 4 KB
 * page so the A32 side can reach every block through a single mapping.
 * Must match the A32 responder (a32_to_m55_responder.c).
 *
 *   MHU0 heap: ctrl @ 0x027DD000, mem @ 0x027DD100 (size 0x700)
 *   MHU1 heap: ctrl @ 0x027DE000, mem @ 0x027DE100 (size 0x700)
 *
 * Addresses come from mhu_doorbell_heap.h.
 */
#if IS_ENABLED(CONFIG_USE_MHU1)
#define SHARED_HEAP_CTRL  SHARED_HEAP_HEA32_MHU1_CTRL
#define SHARED_HEAP_MEM   SHARED_HEAP_HEA32_MHU1_MEM
#else
#define SHARED_HEAP_CTRL  SHARED_HEAP_HEA32_MHU0_CTRL
#define SHARED_HEAP_MEM   SHARED_HEAP_HEA32_MHU0_MEM
#endif

#if IS_ENABLED(CONFIG_USE_MHU1)
#define MHU_NAME "MHU1"
#define MHU_R_ALIAS apssmhu1r
#define MHU_S_ALIAS apssmhu1s
#else
#define MHU_NAME "MHU0"
#define MHU_R_ALIAS apssmhu0r
#define MHU_S_ALIAS apssmhu0s
#endif

const struct device *mhu_rx_dev;
const struct device *mhu_tx_dev;

static volatile bool doorbell_tx_done;
static volatile bool doorbell_rx_received;
static volatile uint32_t rx_doorbell_addr;

static void mhu_rx_callback(const struct device *dev, void *user_data,
			    uint32_t id, volatile void *data)
{
	ARG_UNUSED(dev);
	ARG_UNUSED(user_data);
	ARG_UNUSED(id);

	/* Keep the ISR minimal: no printk here (blocking/latency in interrupt
	 * context). The main loop logs the doorbell in thread context.
	 */
	rx_doorbell_addr = *((uint32_t *)data);
	doorbell_rx_received = true;
}

static void mhu_tx_callback(const struct device *dev, void *user_data,
			    uint32_t id, volatile void *data)
{
	ARG_UNUSED(dev);
	ARG_UNUSED(user_data);
	ARG_UNUSED(id);
	ARG_UNUSED(data);

	/* Keep the ISR minimal: no printk here. */
	doorbell_tx_done = true;
}

static uint32_t calc_checksum(const uint8_t *buf, uint32_t len)
{
	uint32_t sum = 0;

	for (uint32_t i = 0; i < len; i++) {
		sum += buf[i];
	}
	return sum;
}

int main(void)
{
	int iter;
	struct sys_heap *heap = (struct sys_heap *)SHARED_HEAP_CTRL;

	printk("\n==========================================\n");
	printk("M55 -> A32 : %s Doorbell + Shared SRAM1 heap (initiator)\n", MHU_NAME);
	printk("  Shared heap ctrl: 0x%08x\n", SHARED_HEAP_CTRL);
	printk("  Shared heap mem : 0x%08x (size 0x%x)\n",
	       SHARED_HEAP_MEM, SHARED_HEAP_SIZE);
	printk("==========================================\n");

	mhu_rx_dev = DEVICE_DT_GET(DT_ALIAS(MHU_R_ALIAS));
	mhu_tx_dev = DEVICE_DT_GET(DT_ALIAS(MHU_S_ALIAS));

	if (!device_is_ready(mhu_rx_dev) || !device_is_ready(mhu_tx_dev)) {
		printk("ERROR: %s devices not ready!\n", MHU_NAME);
		return -1;
	}
	printk("%s devices ready\n", MHU_NAME);

	ipm_register_callback(mhu_rx_dev, mhu_rx_callback, NULL);
	ipm_register_callback(mhu_tx_dev, mhu_tx_callback, NULL);
	ipm_set_enabled(mhu_rx_dev, true);

	/* Initialise the cross-core heap in shared SRAM. Both the control
	 * block and the managed memory live in shared SRAM so the allocated
	 * block address can be shared with A32. Flush so the initialised heap
	 * is visible to the (non-cacheable) A32 mapping.
	 */
	sys_heap_init(heap, (void *)SHARED_HEAP_MEM, SHARED_HEAP_SIZE);
	CACHE_CLEAN(SHARED_HEAP_CTRL, SHARED_HEAP_SPAN);

	int completed = 0;
	int errors = 0;

	for (iter = 0; iter < ITERATIONS; iter++) {
		/* --- Pick up the heap state freed in the previous iteration --- */
		CACHE_INVALIDATE(SHARED_HEAP_CTRL, SHARED_HEAP_SPAN);

		/* --- Dynamically allocate a message block from the heap --- */
		volatile struct shared_msg *tx_msg =
				sys_heap_alloc(heap, sizeof(struct shared_msg));

		if (tx_msg == NULL) {
			printk("ERROR: sys_heap_alloc failed (iter=%d)\n", iter);
			errors++;
			if (errors >= MAX_ERRORS)
				break;
			continue;
		}

		uint32_t block_addr = (uint32_t)tx_msg;

		/* --- Write test data into the allocated block --- */
		tx_msg->magic    = MAGIC_HE;
		tx_msg->msg_id   = iter;
		tx_msg->data_len = 16;

		/* Fill payload with test pattern */
		for (uint32_t j = 0; j < tx_msg->data_len; j++) {
			tx_msg->data[j] = (uint8_t)(iter + j);
		}
		/* Zero-pad unused data[] bytes */
		memset((void *)&tx_msg->data[tx_msg->data_len], 0,
		       MAX_PAYLOAD - tx_msg->data_len);
		tx_msg->checksum = calc_checksum((const uint8_t *)tx_msg->data,
						 tx_msg->data_len);

		/* --- Flush D-cache so A32 sees the allocation and payload --- */
		CACHE_CLEAN(SHARED_HEAP_CTRL, SHARED_HEAP_SPAN);

		printk("[%d] M55->A32: alloc block @ 0x%08x msg_id=%u len=%u "
		       "cksum=0x%x\n", iter, block_addr, tx_msg->msg_id,
		       tx_msg->data_len, tx_msg->checksum);

		/* --- Ring doorbell to A32 with the allocated block address --- */
		doorbell_tx_done = false;
		doorbell_rx_received = false;
		uint32_t doorbell_val = block_addr;

		int send_ret = ipm_send(mhu_tx_dev, 0, 0, &doorbell_val, 4);

		if (send_ret != 0) {
			printk("ERROR: ipm_send failed: %d\n", send_ret);
			errors++;
			if (errors >= MAX_ERRORS)
				break;
			continue;
		}

		int waited = 0;

		while (!doorbell_tx_done && waited < TX_TIMEOUT_MS) {
			k_sleep(K_MSEC(1));
			waited++;
		}
		if (!doorbell_tx_done) {
			printk("ERROR: TX timeout (%d ms)\n", TX_TIMEOUT_MS);
			errors++;
			if (errors >= MAX_ERRORS)
				break;
			continue;
		}
		printk("M55: Doorbell TX done\n");

		/* --- Wait for A32's acknowledgment doorbell --- */
		waited = 0;
		while (!doorbell_rx_received && waited < RX_TIMEOUT_MS) {
			k_sleep(K_MSEC(1));
			waited++;
		}
		if (!doorbell_rx_received) {
			printk("ERROR: Timeout waiting for A32 response "
			       "(%d ms)\n", RX_TIMEOUT_MS);
			errors++;
			if (errors >= MAX_ERRORS)
				break;
			continue;
		}
		printk("M55: Doorbell RX addr=0x%08x\n", rx_doorbell_addr);

		/* A32 writes its response into the same block and rings back
		 * with the block address as an acknowledgment.
		 */
		if (rx_doorbell_addr != block_addr) {
			printk("[%d] A32->M55: FAIL ack addr 0x%08x != "
			       "block 0x%08x\n", iter, rx_doorbell_addr,
			       block_addr);
			sys_heap_free(heap, (void *)block_addr);
			CACHE_CLEAN(SHARED_HEAP_CTRL, SHARED_HEAP_SPAN);
			errors++;
			if (errors >= MAX_ERRORS)
				break;
			continue;
		}

		/* --- Invalidate D-cache before reading A32's response --- */
		CACHE_INVALIDATE(SHARED_HEAP_CTRL, SHARED_HEAP_SPAN);

		volatile struct shared_msg *incoming =
				(volatile struct shared_msg *)block_addr;
		bool ok = true;

		if (incoming->magic != MAGIC_A32) {
			printk("ERROR: Bad magic 0x%08x (expected 0x%08x)\n",
			       incoming->magic, MAGIC_A32);
			ok = false;
		} else if (incoming->msg_id != (uint32_t)iter) {
			printk("ERROR: msg_id mismatch: got %u, expected %d\n",
			       incoming->msg_id, iter);
			ok = false;
		} else if (incoming->data_len > MAX_PAYLOAD) {
			printk("ERROR: data_len %u exceeds MAX_PAYLOAD\n",
			       incoming->data_len);
			ok = false;
		} else {
			uint32_t rx_len = incoming->data_len;
			uint32_t computed_cksum = calc_checksum(
					(const uint8_t *)incoming->data, rx_len);

			printk("[%d] A32->M55: block @ 0x%08x msg_id=%u len=%u "
			       "cksum=0x%x/0x%x %s\n\n", iter, block_addr,
			       incoming->msg_id, rx_len, computed_cksum,
			       incoming->checksum,
			       (computed_cksum == incoming->checksum) ?
			       "PASS" : "FAIL");
			ok = (computed_cksum == incoming->checksum);
		}

		/* --- Free the block back to the shared heap --- */
		sys_heap_free(heap, (void *)block_addr);
		CACHE_CLEAN(SHARED_HEAP_CTRL, SHARED_HEAP_SPAN);

		if (ok) {
			completed++;
		} else {
			errors++;
		}

		if (errors >= MAX_ERRORS) {
			printk("ERROR: Too many errors (%d), aborting\n",
			       errors);
			break;
		}

		/* Small delay between iterations */
		k_sleep(K_MSEC(500));
	}

	ipm_set_enabled(mhu_rx_dev, false);
	printk("Done: %d/%d passed, %d failed\n",
	       completed, ITERATIONS, errors);
	return (completed + errors == ITERATIONS) ? 0 : -1;
}
```
